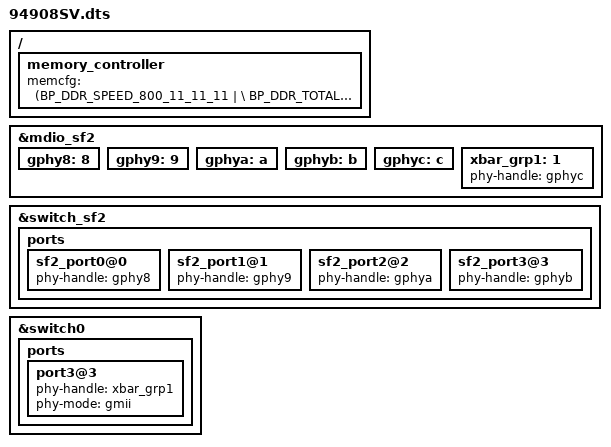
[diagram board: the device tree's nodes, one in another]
#include "4908.dtsi"

/ {
    memory_controller {
        memcfg = <(BP_DDR_SPEED_800_11_11_11 | \
                   BP_DDR_TOTAL_SIZE_1024MB  | \
                   BP_DDR_DEVICE_WIDTH_16    | \
                   BP_DDR_TOTAL_WIDTH_32BIT  | \
                   BP_DDR_SSC_CONFIG_1)>;
    };
};

&mdio_sf2 {
	/* PHYs directly connected to SF2 */
	gphy8:8 {
		status = "okay";
	};
	gphy9:9 {
		status = "okay";
	};
	gphya:a {
		status = "okay";
	};
	gphyb:b {
		status = "okay";
	};

	/* PHYs connected to crossbar */
	gphyc:c {
		status = "okay";
	};

	/* Crossbar groups */
	xbar_grp1:1 {
		phy-handle = <&gphyc>;
		status = "okay";
	};
};

&switch_sf2 {
	ports {
		sf2_port0@0 {
			phy-handle = <&gphy8>;
			status = "okay";
		};

		sf2_port1@1 {
			phy-handle = <&gphy9>;
			status = "okay";
		};

		sf2_port2@2 {
			phy-handle = <&gphya>;
			status = "okay";
		};

		sf2_port3@3 {
			phy-handle = <&gphyb>;
			status = "okay";
		};
	};
};

&switch0 {
	ports {
		
		port3@3 {
			phy-handle = <&xbar_grp1>;
			phy-mode = "gmii";
			status = "okay";
		};
	};
};
